# GD32F10x_CL register map
File version: 1.0
CPU: CM3 r2p1, little endian, no MPU, no FPU, 4 interrupt priority bits
Registers are 32-bit, read-write, reset 0x0 unless marked. A register's access mark holds for its fields unless they carry their own. Offsets are from the block's base; [hi:lo] are bit positions; {n}, {i} and the like mark numbered series; 'fields as' and 'values as' point back to an identical list.

## TIMER5 — Basic-timers
Base 0x40001000
Same registers: TIMER6 0x40001400
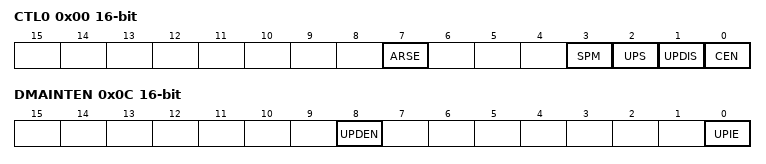
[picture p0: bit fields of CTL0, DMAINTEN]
0x00 CTL0 16-bit — control register 0
  [7] ARSE — Auto-reload shadow enable
  [3] SPM — Single pulse mode
  [2] UPS — Update source
  [1] UPDIS — Update disable
  [0] CEN — Counter enable
0x04 CTL1 16-bit — control register 1
  [6:4] MMC — Master mode control
0x0C DMAINTEN 16-bit — DMA/Interrupt enable register
  [8] UPDEN — Update DMA request enable
  [0] UPIE — Update interrupt enable
0x10 INTF 16-bit — Interrupt flag register
  [0] UPIF — Update interrupt flag
0x14 SWEVG 16-bit wo — event generation register
  [0] UPG — Update generation
0x24 CNT 16-bit — Counter register
  [15:0] CNT — Low counter value
0x28 PSC 16-bit — Prescaler register
  [15:0] PSC — Prescaler value of the counter clock
0x2C CAR 16-bit — Counter auto reload register
  [15:0] CARL — Counter auto reload value

## USART0 — Universal synchronous asynchronous receiver transmitter
Base 0x40013800
Same registers: USART1 0x40004400, USART2 0x40004800
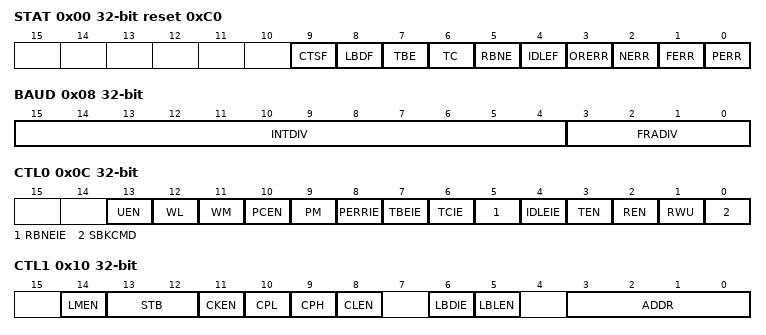
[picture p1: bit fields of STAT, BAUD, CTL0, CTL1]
0x00 STAT access per field reset 0xC0 — Status register
  [9] CTSF rw — CTS change flag
  [8] LBDF rw — LIN break detection flag
  [7] TBE ro — Transmit data buffer empty
  [6] TC rw — Transmission complete
  [5] RBNE rw — Read data buffer not empty
  [4] IDLEF ro — IDLE frame detected flag
  [3] ORERR ro — Overrun error
  [2] NERR ro — Noise error flag
  [1] FERR ro — Frame error flag
  [0] PERR ro — Parity error flag
0x04 DATA
  [8:0] DATA — Transmit or read data value
0x08 BAUD — Baud rate register
  [15:4] INTDIV — Integer part of baud-rate divider
  [3:0] FRADIV — Fraction part of baud-rate divider
0x0C CTL0 — Control register 0
  [13] UEN — USART enable
  [12] WL — Word length
  [11] WM — Wakeup method in mute mode
  [10] PCEN — Parity check function enable
  [9] PM — Parity mode
  [8] PERRIE — Parity error interrupt enable
  [7] TBEIE — Transmitter buffer empty interrupt enable
  [6] TCIE — Transmission complete interrupt enable
  [5] RBNEIE — Read data buffer not empty interrupt and overrun error interrupt enable
  [4] IDLEIE — IDLE line detected interrupt enable
  [3] TEN — Transmitter enable
  [2] REN — Receiver enable
  [1] RWU — Receiver wakeup from mute mode
  [0] SBKCMD — Send break command
0x10 CTL1 — Control register 1
  [14] LMEN — LIN mode enable
  [13:12] STB — STOP bits length
  [11] CKEN — CK pin enable
  [10] CPL — Clock polarity
  [9] CPH — Clock phase
  [8] CLEN — CK Length
  [6] LBDIE — LIN break detection interrupt enable
  [5] LBLEN — LIN break frame length
  [3:0] ADDR — Address of the USART
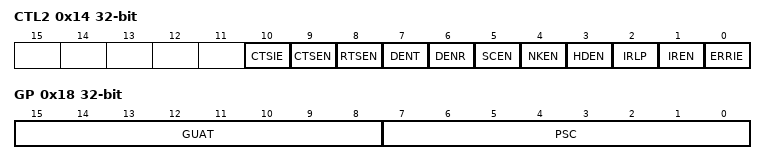
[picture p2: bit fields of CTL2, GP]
0x14 CTL2 — Control register 2
  [10] CTSIE — CTS interrupt enable
  [9] CTSEN — CTS enable
  [8] RTSEN — RTS enable
  [7] DENT — DMA request enable for transmission
  [6] DENR — DMA request enable for reception
  [5] SCEN — Smartcard mode enable
  [4] NKEN — Smartcard NACK enable
  [3] HDEN — Half-duplex selection
  [2] IRLP — IrDA low-power
  [1] IREN — IrDA mode enable
  [0] ERRIE — Error interrupt enable
0x18 GP — Guard time and prescaler register
  [15:8] GUAT — Guard time value in Smartcard mode
  [7:0] PSC — Prescaler value

## UART3 — Universal asynchronous receiver transmitter
Base 0x40004C00
Same registers: UART4 0x40005000
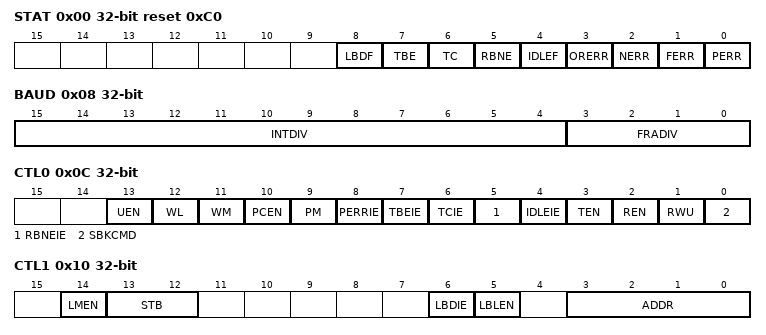
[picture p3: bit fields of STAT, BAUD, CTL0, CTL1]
0x00 STAT access per field reset 0xC0 — Status register
  [8] LBDF rw — LIN break detection flag
  [7] TBE ro — Transmit data buffer empty
  [6] TC rw — Transmission complete
  [5] RBNE rw — Read data buffer not empty
  [4] IDLEF ro — IDLE frame detected flag
  [3] ORERR ro — Overrun error
  [2] NERR ro — Noise error flag
  [1] FERR ro — Frame error flag
  [0] PERR ro — Parity error flag
0x04 DATA
  [8:0] DATA — Transmit or read data value
0x08 BAUD — Baud rate register
  [15:4] INTDIV — Integer part of baud-rate divider
  [3:0] FRADIV — Fraction part of baud-rate divider
0x0C CTL0 — Control register 0
  [13] UEN — USART enable
  [12] WL — Word length
  [11] WM — Wakeup method in mute mode
  [10] PCEN — Parity check function enable
  [9] PM — Parity mode
  [8] PERRIE — Parity error interrupt enable
  [7] TBEIE — Transmitter buffer empty interrupt enable
  [6] TCIE — Transmission complete interrupt enable
  [5] RBNEIE — Read data buffer not empty interrupt and overrun error interrupt enable
  [4] IDLEIE — IDLE line detected interrupt enable
  [3] TEN — Transmitter enable
  [2] REN — Receiver enable
  [1] RWU — Receiver wakeup from mute mode
  [0] SBKCMD — Send break command
0x10 CTL1 — Control register 1
  [14] LMEN — LIN mode enable
  [13:12] STB — STOP bits length
  [6] LBDIE — LIN break detection interrupt enable
  [5] LBLEN — LIN break frame length
  [3:0] ADDR — Address of the USART
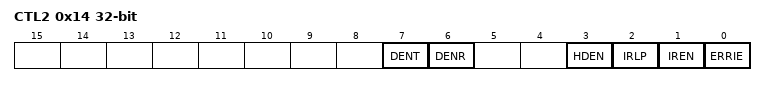
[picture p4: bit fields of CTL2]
0x14 CTL2 — Control register 2
  [7] DENT — DMA request enable for transmission
  [6] DENR — DMA request enable for reception
  [3] HDEN — Half-duplex selection
  [2] IRLP — IrDA low-power
  [1] IREN — IrDA mode enable
  [0] ERRIE — Error interrupt enable
0x18 GP — Guard time and prescaler register
  [7:0] PSC — Prescaler value

## USBFS_HOST — USB on the go full speed host
Base 0x50000400
0x00 HCTL — host configuration register (HCTL)
  [1:0] CLKSEL — clock select for USB clock
0x04 HFT reset 0xBB80 — Host frame interval register
  [15:0] FRI — Frame interval
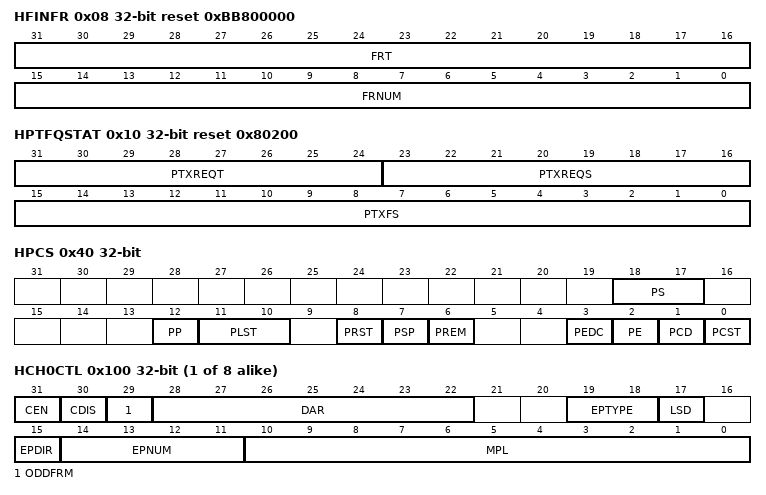
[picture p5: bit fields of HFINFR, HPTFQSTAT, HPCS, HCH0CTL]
0x08 HFINFR ro reset 0xBB800000 — FS host frame number/frame time remaining register (HFINFR)
  [31:16] FRT — Frame remaining time
  [15:0] FRNUM — Frame number
0x10 HPTFQSTAT ro reset 0x80200 — Host periodic transmit FIFO/queue status register (HPTFQSTAT)
  [31:24] PTXREQT — Top of the periodic transmit request queue
  [23:16] PTXREQS — Periodic transmit request queue space available
  [15:0] PTXFS — Periodic transmit data FIFO space available
0x14 HACHINT ro — Host all channels interrupt register
  [7:0] HACHINT — Host all channel interrupts
0x18 HACHINTEN — host all channels interrupt mask register
  [7:0] CINTEN — Channel interrupt enable
0x40 HPCS access per field — Host port control and status register (USBFS_HPCS)
  [18:17] PS ro — Port speed
  [12] PP rw — Port power
  [11:10] PLST ro — Port line status
  [8] PRST rw — Port reset
  [7] PSP rw — Port suspend
  [6] PREM rw — Port resume
  [3] PEDC rw — Port enable/disable change
  [2] PE rw — Port enable
  [1] PCD rw — Port connect detected
  [0] PCST ro — Port connect status
{0x100+0x20*i} HCH{i}CTL (i=0..7) — host channel-{i} characteristics register (HCH{i}CTL)
  [31] CEN — Channel enable
  [30] CDIS — Channel disable
  [29] ODDFRM — Odd frame
  [28:22] DAR — Device address
  [19:18] EPTYPE — Endpoint type
  [17] LSD — Low-speed device
  [15] EPDIR — Endpoint direction
  [14:11] EPNUM — Endpoint number
  [10:0] MPL — Maximum packet size
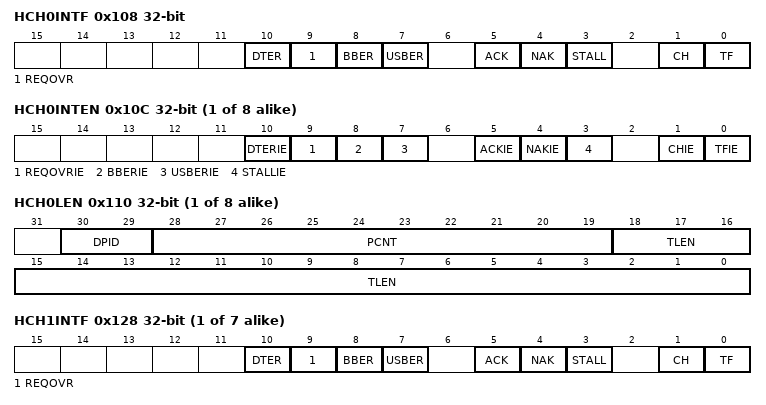
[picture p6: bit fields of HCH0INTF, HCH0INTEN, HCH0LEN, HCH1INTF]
0x108 HCH0INTF — host channel-0 interrupt register (USBFS_HCHxINTF)
  [10] DTER — Data toggle error
  [9] REQOVR — Request queue overrun
  [8] BBER — Babble error
  [7] USBER — USB bus error
  [5] ACK — ACK response received/transmitted interrupt
  [4] NAK — NAK response received interrupt
  [3] STALL — STALL response received interrupt
  [1] CH — Channel halted
  [0] TF — Transfer finished
{0x10C+0x20*i} HCH{i}INTEN (i=0..7) — host channel-{i} interrupt enable register (HCH{i}INTEN)
  [10] DTERIE — Data toggle error interrupt enable
  [9] REQOVRIE — request queue overrun interrupt enable
  [8] BBERIE — Babble error interrupt enable
  [7] USBERIE — USB bus error interrupt enable
  [5] ACKIE — ACK interrupt enable
  [4] NAKIE — NAK interrupt enable
  [3] STALLIE — STALL interrupt enable
  [1] CHIE — Channel halted interrupt enable
  [0] TFIE — Transfer completed interrupt enable
{0x110+0x20*i} HCH{i}LEN (i=0..7) — host channel-{i} transfer length register
  [30:29] DPID — Data PID
  [28:19] PCNT — Packet count
  [18:0] TLEN — Transfer length
{0x108+0x20*i} HCH{i}INTF (i=1..7) — host channel-{i} interrupt register (HCH{i}INTF)
  fields as HCH0INTF

## USBFS_PWRCLK — USB on the go full speed
Base 0x50000E00
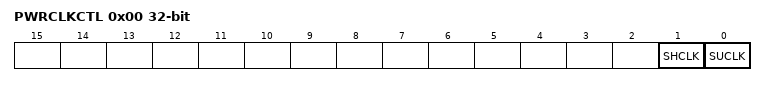
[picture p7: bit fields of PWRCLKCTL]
0x00 PWRCLKCTL — power and clock gating control register (PWRCLKCTL)
  [1] SHCLK — Stop HCLK
  [0] SUCLK — Stop the USB clock

## WWDGT — Window watchdog timer
Base 0x40002C00
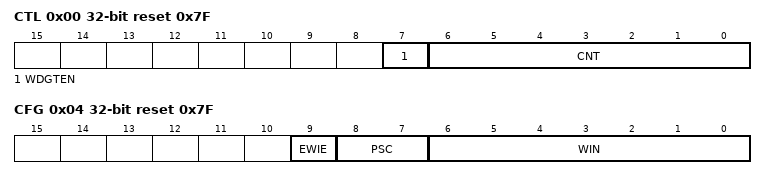
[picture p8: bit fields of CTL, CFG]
0x00 CTL reset 0x7F — Control register
  [7] WDGTEN — Activation bit
  [6:0] CNT — 7-bit counter
0x04 CFG reset 0x7F — Configuration register
  [9] EWIE — Early wakeup interrupt
  [8:7] PSC — Prescaler
  [6:0] WIN — 7-bit window value
0x08 STAT — Status register
  [0] EWIF — Early wakeup interrupt flag
